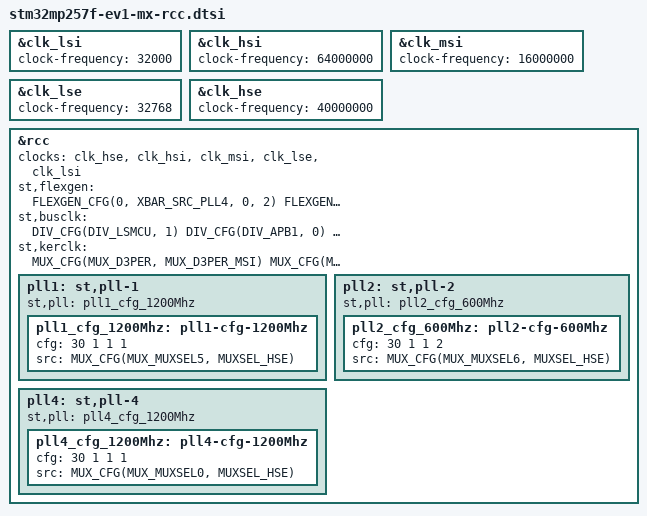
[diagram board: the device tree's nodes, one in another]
// SPDX-License-Identifier: (GPL-2.0-or-later OR BSD-3-Clause)
/*
 * Copyright (C) 2024, STMicroelectronics - All Rights Reserved
 * Author: STM32CubeMX code generation for STMicroelectronics.
 */

/* For more information on Device Tree configuration, please refer to
 * https://wiki.st.com/stm32mpu/wiki/Category:Device_tree_configuration
 */

&clk_lsi {
	clock-frequency = <32000>;

	/* USER CODE BEGIN clk_lsi */
	/* USER CODE END clk_lsi */
};
&clk_hsi {
	clock-frequency = <64000000>;

	/* USER CODE BEGIN clk_hsi */
	/* USER CODE END clk_hsi */
};
&clk_msi {
	clock-frequency = <16000000>;

	/* USER CODE BEGIN clk_msi */
	/* USER CODE END clk_msi */
};
&clk_lse {
	clock-frequency = <32768>;

	/* USER CODE BEGIN clk_lse */
	/* USER CODE END clk_lse */
};
&clk_hse {
	clock-frequency = <40000000>;

	/* USER CODE BEGIN clk_hse */
	/* USER CODE END clk_hse */
};

&rcc{

	clocks = <&clk_hse>, <&clk_hsi>, <&clk_msi>, <&clk_lse>, <&clk_lsi>;
	clock-names = "clk-hse", "clk-hsi", "clk-msi", "clk-lse", "clk-lsi";

	st,flexgen = <

		FLEXGEN_CFG(0, XBAR_SRC_PLL4, 0, 2)
		FLEXGEN_CFG(1, XBAR_SRC_PLL4, 0, 5)
		FLEXGEN_CFG(2, XBAR_SRC_PLL4, 0, 1)
		FLEXGEN_CFG(3, XBAR_SRC_PLL4, 0, 2)
		FLEXGEN_CFG(4, XBAR_SRC_PLL4, 0, 3)
		FLEXGEN_CFG(5, XBAR_SRC_PLL4, 0, 2)
		FLEXGEN_CFG(6, XBAR_SRC_PLL4, 0, 1)
		FLEXGEN_CFG(8, XBAR_SRC_HSI_KER, 0, 0)
		FLEXGEN_CFG(15, XBAR_SRC_PLL4, 0, 11)
		FLEXGEN_CFG(33, XBAR_SRC_PLL4, 0, 23)
		FLEXGEN_CFG(43, XBAR_SRC_PLL4, 0, 23)
		FLEXGEN_CFG(44, XBAR_SRC_PLL4, 0, 5)
		FLEXGEN_CFG(45, XBAR_SRC_PLL4, 0, 2)
		FLEXGEN_CFG(51, XBAR_SRC_PLL4, 0, 5)
		FLEXGEN_CFG(59, XBAR_SRC_PLL4, 0, 1)
		FLEXGEN_CFG(63, XBAR_SRC_PLL4, 0, 2)
	>;

	st,busclk = <
		DIV_CFG(DIV_LSMCU, 1)
		DIV_CFG(DIV_APB1, 0)
		DIV_CFG(DIV_APB2, 0)
		DIV_CFG(DIV_APB3, 0)
		DIV_CFG(DIV_APB4, 0)
		DIV_CFG(DIV_APBDBG, 0)
	>;

	st,kerclk = <
		MUX_CFG(MUX_D3PER, MUX_D3PER_MSI)

		MUX_CFG(MUX_RTC, MUX_RTC_LSE)

	>;

	pll1:st,pll-1 {
		st,pll = < &pll1_cfg_1200Mhz >;

		pll1_cfg_1200Mhz: pll1-cfg-1200Mhz{
			cfg = <30 1 1 1>;
			src = <MUX_CFG(MUX_MUXSEL5, MUXSEL_HSE)>;
		};
		/* USER CODE BEGIN pll1 */
		/* USER CODE END pll1 */
	};

	pll2:st,pll-2 {
		st,pll = < &pll2_cfg_600Mhz >;

		pll2_cfg_600Mhz: pll2-cfg-600Mhz{
			cfg = <30 1 1 2>;
			src = <MUX_CFG(MUX_MUXSEL6, MUXSEL_HSE)>;
		};
		/* USER CODE BEGIN pll2 */
		/* USER CODE END pll2 */
	};

	pll4:st,pll-4 {
		st,pll = < &pll4_cfg_1200Mhz >;

		pll4_cfg_1200Mhz: pll4-cfg-1200Mhz{
			cfg = <30 1 1 1>;
			src = <MUX_CFG(MUX_MUXSEL0, MUXSEL_HSE)>;
		};
		/* USER CODE BEGIN pll4 */
		/* USER CODE END pll4 */
	};

	/* USER CODE BEGIN rcc */
	/* USER CODE END rcc */
};
